# HDSC_HC32F4A0 register map
Vendor: HDSC; Series: ARMCM4; File version: 1.0
CPU: CM4 r0p1, little endian, MPU, FPU, 4 interrupt priority bits
Registers are 32-bit, read-write, reset 0x0 unless marked. A register's access mark holds for its fields unless they carry their own. Offsets are from the block's base; [hi:lo] are bit positions; {n}, {i} and the like mark numbered series.

## ADC1
Base 0x40040000
0x00 STR 8-bit
  [0] STRT
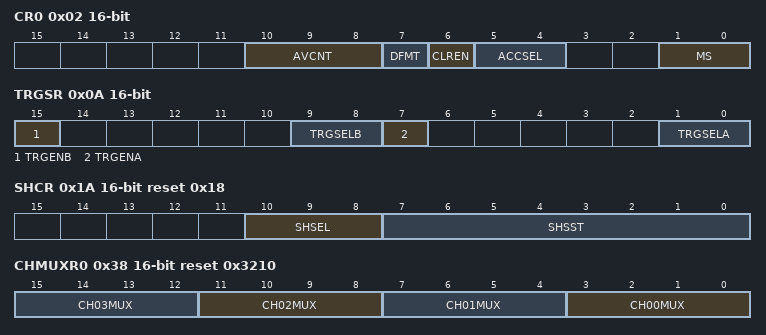
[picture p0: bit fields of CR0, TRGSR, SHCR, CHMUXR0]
0x02 CR0 16-bit
  [10:8] AVCNT, [7] DFMT, [6] CLREN, [5:4] ACCSEL, [1:0] MS
0x04 CR1 16-bit
  [2] RSCHSEL
0x0A TRGSR 16-bit
  [15] TRGENB, [9:8] TRGSELB, [7] TRGENA, [1:0] TRGSELA
0x0C CHSELRA
  [15:0] CHSELA
0x10 CHSELRB
  [15:0] CHSELB
0x14 AVCHSELR
  [15:0] AVCHSEL
0x18 EXCHSELR 8-bit
  [0] EXCHSEL
0x1A SHCR 16-bit reset 0x18
  [10:8] SHSEL, [7:0] SHSST
{0x20+i} SSTR{i} 8-bit reset 0xB (i=0..15)
0x30 SSTRL 8-bit reset 0xB
0x38 CHMUXR0 16-bit reset 0x3210
  [4n+3:4n] CH{n:02}MUX (n=0..3)
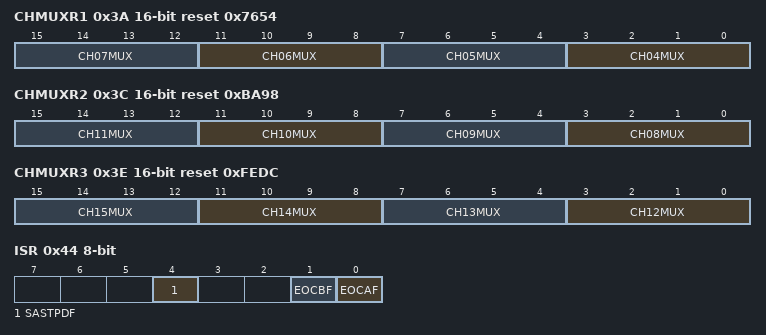
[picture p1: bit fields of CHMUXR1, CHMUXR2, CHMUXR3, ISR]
0x3A CHMUXR1 16-bit reset 0x7654
  [4n-13:4n-16] CH{n:02}MUX (n=4..7)
0x3C CHMUXR2 16-bit reset 0xBA98
  [4n-29:4n-32] CH{n:02}MUX (n=8..11)
0x3E CHMUXR3 16-bit reset 0xFEDC
  [4n-45:4n-48] CH{n}MUX (n=12..15)
0x44 ISR 8-bit ro
  [4] SASTPDF, [1] EOCBF, [0] EOCAF
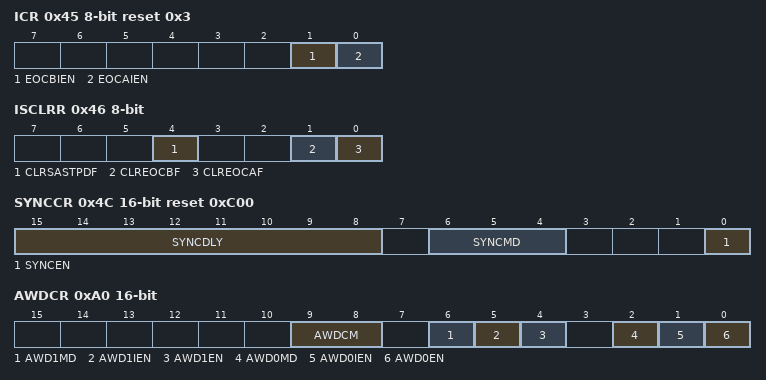
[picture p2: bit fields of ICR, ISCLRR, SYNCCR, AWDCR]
0x45 ICR 8-bit reset 0x3
  [1] EOCBIEN, [0] EOCAIEN
0x46 ISCLRR 8-bit
  [4] CLRSASTPDF, [1] CLREOCBF, [0] CLREOCAF
0x4C SYNCCR 16-bit reset 0xC00
  [15:8] SYNCDLY, [6:4] SYNCMD, [0] SYNCEN
{0x50+2i} DR{i} 16-bit ro (i=0..15)
0xA0 AWDCR 16-bit
  [9:8] AWDCM, [6] AWD1MD, [5] AWD1IEN, [4] AWD1EN, [2] AWD0MD, [1] AWD0IEN, [0] AWD0EN
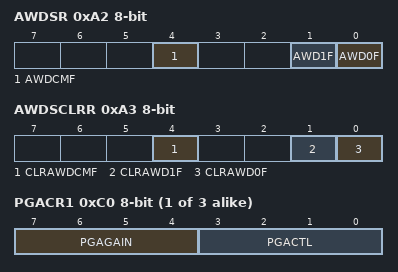
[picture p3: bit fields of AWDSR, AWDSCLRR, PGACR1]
0xA2 AWDSR 8-bit ro
  [4] AWDCMF, [1] AWD1F, [0] AWD0F
0xA3 AWDSCLRR 8-bit wo
  [4] CLRAWDCMF, [1] CLRAWD1F, [0] CLRAWD0F
0xA4 AWD0DR0 16-bit
0xA6 AWD0DR1 16-bit reset 0xFFFF
0xA8 AWD0CHSR 8-bit
  [4:0] AWDCH
0xAC AWD1DR0 16-bit
0xAE AWD1DR1 16-bit reset 0xFFFF
0xB0 AWD1CHSR 8-bit
  [4:0] AWDCH
{0xBF+i} PGACR{i} 8-bit (i=1..3)
  [7:4] PGAGAIN, [3:0] PGACTL
0xC4 PGAVSSENR 8-bit
  [2:0] PGAVSSEN

## ADC2
Base 0x40040400
Registers as ADC1, without SHCR, SYNCCR, PGACR2, PGACR3; these are added or differ:
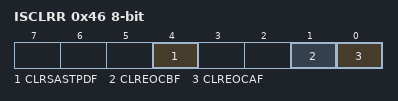
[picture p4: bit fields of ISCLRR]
0x46 ISCLRR 8-bit wo
  [4] CLRSASTPDF, [1] CLREOCBF, [0] CLREOCAF
0xC4 PGAVSSENR 8-bit
  [0] PGAVSSEN

## ADC3
Base 0x40040800
Registers as ADC2, without PGACR1, PGAVSSENR; these are added or differ:
0x0C CHSELRA
  [19:0] CHSELA
0x10 CHSELRB
  [19:0] CHSELB
0x14 AVCHSELR
  [19:0] AVCHSEL
{0x50+2i} DR{i} 16-bit ro (i=16..19)

## AES
Base 0x40008000
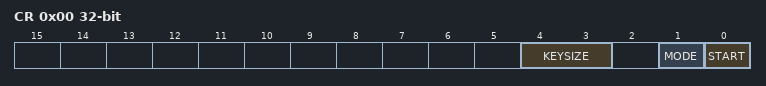
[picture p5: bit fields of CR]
0x00 CR
  [4:3] KEYSIZE, [1] MODE, [0] START
{0x10+4i} DR{i} (i=0..3)
{0x20+4i} KR{i} (i=0..7)

## AOS
Base 0x40010800
0x00 INTSFTTRG wo
  [0] STRG
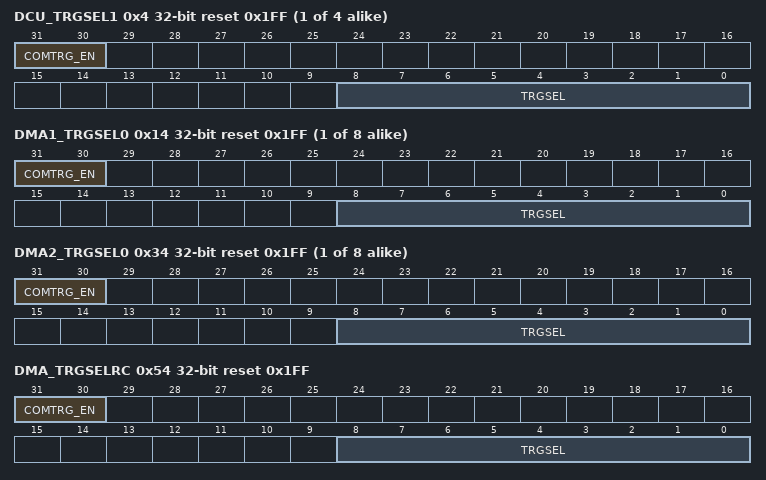
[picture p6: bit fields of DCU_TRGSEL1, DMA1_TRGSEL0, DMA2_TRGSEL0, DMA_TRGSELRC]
{0x0+4i} DCU_TRGSEL{i} reset 0x1FF (i=1..4)
  [31:30] COMTRG_EN, [8:0] TRGSEL
{0x14+4i} DMA1_TRGSEL{i} reset 0x1FF (i=0..7)
  [31:30] COMTRG_EN, [8:0] TRGSEL
{0x34+4i} DMA2_TRGSEL{i} reset 0x1FF (i=0..7)
  [31:30] COMTRG_EN, [8:0] TRGSEL
0x54 DMA_TRGSELRC reset 0x1FF
  [31:30] COMTRG_EN, [8:0] TRGSEL
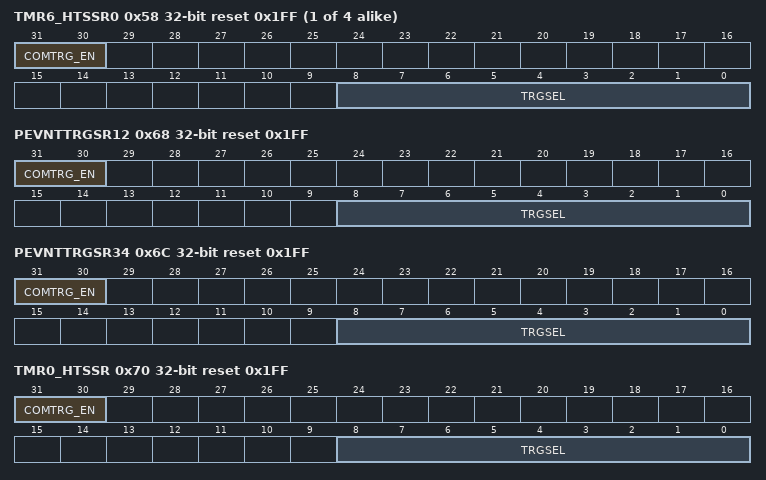
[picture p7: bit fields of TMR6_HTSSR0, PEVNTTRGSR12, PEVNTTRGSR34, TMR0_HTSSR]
{0x58+4i} TMR6_HTSSR{i} reset 0x1FF (i=0..3)
  [31:30] COMTRG_EN, [8:0] TRGSEL
0x68 PEVNTTRGSR12 reset 0x1FF
  [31:30] COMTRG_EN, [8:0] TRGSEL
0x6C PEVNTTRGSR34 reset 0x1FF
  [31:30] COMTRG_EN, [8:0] TRGSEL
0x70 TMR0_HTSSR reset 0x1FF
  [31:30] COMTRG_EN, [8:0] TRGSEL
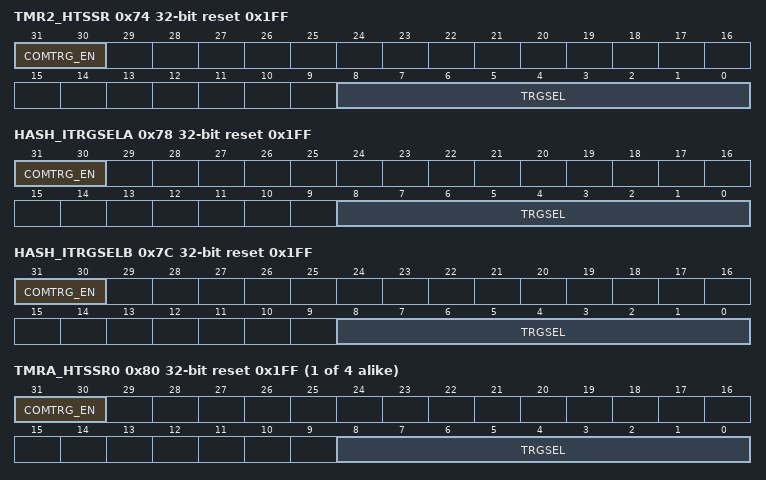
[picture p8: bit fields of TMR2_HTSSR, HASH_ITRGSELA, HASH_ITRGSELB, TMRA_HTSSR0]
0x74 TMR2_HTSSR reset 0x1FF
  [31:30] COMTRG_EN, [8:0] TRGSEL
0x78 HASH_ITRGSELA reset 0x1FF
  [31:30] COMTRG_EN, [8:0] TRGSEL
0x7C HASH_ITRGSELB reset 0x1FF
  [31:30] COMTRG_EN, [8:0] TRGSEL
{0x80+4i} TMRA_HTSSR{i} reset 0x1FF (i=0..3)
  [31:30] COMTRG_EN, [8:0] TRGSEL
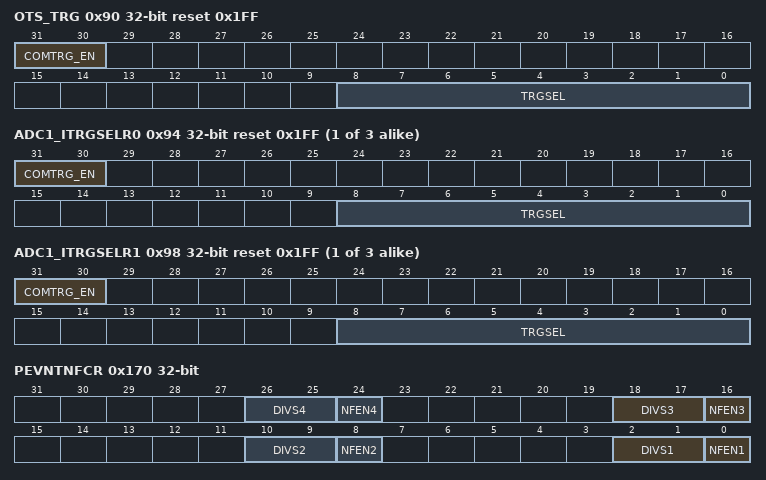
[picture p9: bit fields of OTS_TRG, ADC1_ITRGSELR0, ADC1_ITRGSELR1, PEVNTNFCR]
0x90 OTS_TRG reset 0x1FF
  [31:30] COMTRG_EN, [8:0] TRGSEL
{0x8C+8i} ADC{i}_ITRGSELR0 reset 0x1FF (i=1..3)
  [31:30] COMTRG_EN, [8:0] TRGSEL
{0x90+8i} ADC{i}_ITRGSELR1 reset 0x1FF (i=1..3)
  [31:30] COMTRG_EN, [8:0] TRGSEL
0xAC COMTRG1 reset 0x1FF
  [8:0] TRGSEL
0xB0 COMTRG2 reset 0x1FF
  [8:0] TRGSEL
{0xE4+0x1C*i} PEVNTDIRR{i} (i=1..4)
  [15:0] PDIR
{0xE8+0x1C*i} PEVNTIDR{i} ro (i=1..4)
  [15:0] PIN
{0xEC+0x1C*i} PEVNTODR{i} (i=1..4)
  [15:0] POUT
{0xF0+0x1C*i} PEVNTORR{i} (i=1..4)
  [15:0] POR
{0xF4+0x1C*i} PEVNTOSR{i} (i=1..4)
  [15:0] POS
{0xF8+0x1C*i} PEVNTRISR{i} (i=1..4)
  [15:0] RIS
{0xFC+0x1C*i} PEVNTFAL{i} (i=1..4)
  [15:0] FAL
0x170 PEVNTNFCR
  [8n-6:8n-7] DIVS{n} (n=1..4), [8n-8] NFEN{n} (n=1..4)
